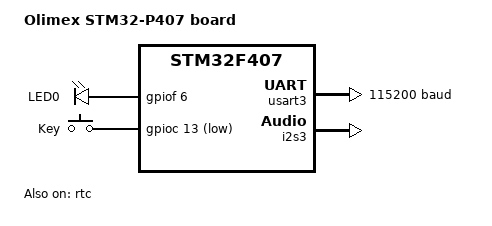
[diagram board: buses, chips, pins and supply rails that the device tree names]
/*
 * Copyright (c) 2017, Erwin Rol <erwin@erwinrol.com>
 *
 * SPDX-License-Identifier: Apache-2.0
 */

/dts-v1/;
#include <st/f4/stm32f407Xg.dtsi>

/ {
	model = "Olimex STM32-P407 board";
	compatible = "olimex,stm32-p407", "st,stm32f407";

	chosen {
		zephyr,console = &usart3;
		zephyr,shell-uart = &usart3;
		zephyr,sram = &sram0;
		zephyr,flash = &flash0;
		zephyr,ccm = &ccm0;
	};

	leds {
		compatible = "gpio-leds";
		green_led_1: led_1 {
			gpios = <&gpiof 6 GPIO_ACTIVE_HIGH>;
			label = "LED0";
		};
	};

	gpio_keys {
		compatible = "gpio-keys";
		user_button: button {
			label = "Key";
			gpios = <&gpioc 13 GPIO_ACTIVE_LOW>;
		};
	};

	aliases {
		led0 = &green_led_1;
		sw0 = &user_button;
		i2s = &i2s3;
	};
};

&usart3 {
	current-speed = <115200>;
	status = "okay";
};

&i2s3 {
	status = "okay";
};

&dma1 {
	status = "okay";
};

&rtc {
	status = "okay";
};
